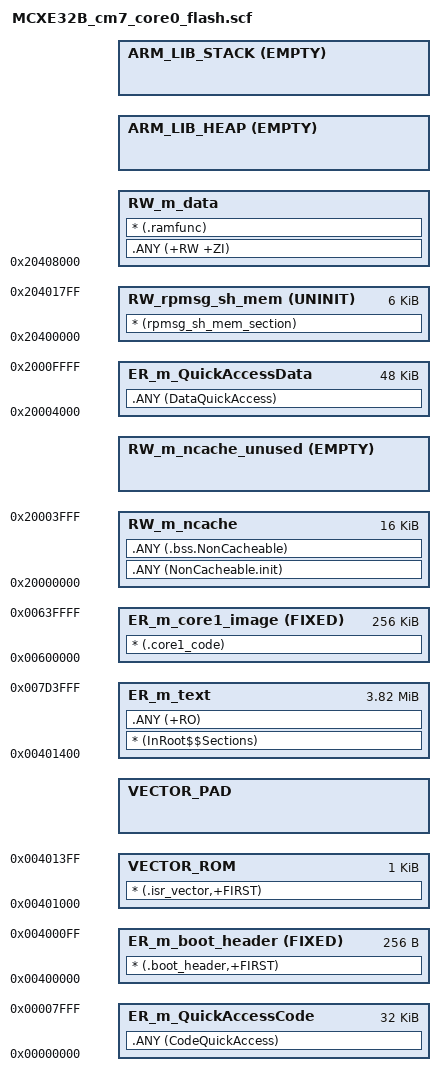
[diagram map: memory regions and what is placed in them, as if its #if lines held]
#!armclang --target=arm-arm-none-eabi -mcpu=cortex-m7 -E -x c

/*
** ###################################################################
**     Processor:           MCXE32BMPB_cm7_core0
**     Compiler:            Keil ARM C/C++ Compiler
**     Reference manual:    MCXE31 RM Rev2
**     Version:             rev. 1.1, 2025-11-07
**     Build:               b260609
**
**     Abstract:
**         Linker file for the Keil ARM C/C++ Compiler
**
**     Copyright 2016 Freescale Semiconductor, Inc.
**     Copyright 2016-2026 NXP
**     SPDX-License-Identifier: BSD-3-Clause
**
**     http:                 www.nxp.com
**     mail:                 support@nxp.com
**
** ###################################################################
*/

#define m_itcm_start                   0x00000000
#define m_itcm_end                     0x00007FFF

#define m_dtcm_start                   0x20000000
#define m_dtcm_end                     0x2000FFFF

#define m_stdby_ram_start              0x20400000
#define m_stdby_ram_end                0x20407FFF

#if (defined(__use_shmem__))
  #define rpmsg_sh_mem_size            0x1800
#else
  #define rpmsg_sh_mem_size            0
#endif
#define rpmsg_sh_mem_start             m_stdby_ram_start

#define m_interrupts_start             0x00401000
#define m_interrupts_size              0x00000400

#define m_boot_header_start            0x00400000
#define m_boot_header_size             0x00000100

#define m_text_start                   0x00401400
#define m_text_size                    0x003D2C00

/* Flash region holding the embedded secondary core (M7_1) image. The secondary
 * is linked to run in place from this address and is programmed together with
 * the primary. The secondary core is released by the application at runtime. */
#define m_core1_image_start            0x00600000
#define m_core1_image_size             0x00040000

/* Shared SRAM is split into two disjoint halves so the primary (M7_0) and the
 * secondary (M7_1) never use the same RAM. core0 owns the lower 144 KB; core1
 * owns the upper 144 KB (see MCXE32B_cm7_core1_flash.scf). The whole window is
 * 0x20408000..0x2044FFFF (288 KB). */
#define m_data_start                   0x20408000
#define m_data_size                    0x00024000

#define m_ncache_size                  0x00004000
#define m_ncache_start                 m_dtcm_start
#define m_ncache_end                   m_ncache_start + m_ncache_size - 1

#define m_qacode_start                 m_itcm_start
#define m_qacode_end                   m_itcm_end
#define m_qadata_start                 m_ncache_end + 1
#define m_qadata_end                   m_dtcm_end

#define m_itcm1_backdoor_start         0x11400000
#define m_itcm1_backdoor_size          0x00008000
#define m_itcm1_backdoor_end           m_itcm1_backdoor_start + m_itcm1_backdoor_size - 1

#define m_dtcm1_backdoor_start         0x21400000
#define m_dtcm1_backdoor_size          0x00010000
#define m_dtcm1_backdoor_end           m_dtcm1_backdoor_start + m_dtcm1_backdoor_size - 1

/* Sizes */
#if (defined(__stack_size__))
  #define Stack_Size                   __stack_size__
#else
  #define Stack_Size                   0x0400
#endif

#if (defined(__heap_size__))
  #define Heap_Size                    __heap_size__
#else
  #define Heap_Size                    0x0400
#endif

LR_m_header m_boot_header_start m_boot_header_size { ; load region size_region
  ER_m_boot_header m_boot_header_start FIXED m_boot_header_size { ; load address = execution address
    * (.boot_header,+FIRST)
  }
}

LR_m_text m_interrupts_start m_interrupts_size+m_text_size { ; load region size_region
  VECTOR_ROM m_interrupts_start m_interrupts_size { ; load address = execution address
    * (.isr_vector,+FIRST)
  }
  VECTOR_PAD +0 FILL 0x0 m_text_start-ImageLimit(VECTOR_ROM) {
  }
  ER_m_text m_text_start m_text_size { ; load address = execution address
    * (InRoot$$Sections)
    .ANY (+RO)
  }

  ER_m_QuickAccessCode   m_qacode_start      m_qacode_end-m_qacode_start+1
  {
    .ANY (CodeQuickAccess)
  }

  ER_m_QuickAccessData   m_qadata_start      m_qadata_end-m_qadata_start+1
  {
    .ANY (DataQuickAccess)
  }

  RW_m_ncache m_ncache_start  m_ncache_size
  {
    .ANY (NonCacheable.init)
    .ANY (.bss.NonCacheable)
  }

  ; Empty region added for MPU configuration
  RW_m_ncache_unused +0 EMPTY m_ncache_size-ImageLength(RW_m_ncache)
  {
  }

  RW_m_data m_data_start m_data_size-Stack_Size-Heap_Size { ; RW data
    .ANY (+RW +ZI)
    * (.ramfunc)
  }

  ARM_LIB_HEAP +0 EMPTY Heap_Size {    ; Heap region growing up
  }
  ARM_LIB_STACK m_data_start+m_data_size EMPTY -Stack_Size { ; Stack region growing down
  }
}

/* Embedded secondary core (M7_1) image, placed at a fixed flash address so it
 * is programmed together with the primary and runs in place from flash. */
LR_m_core1_image m_core1_image_start m_core1_image_size {
  ER_m_core1_image m_core1_image_start FIXED m_core1_image_size {
    * (.core1_code)
  }
}

/* rpmsg-lite shared memory (only consumes RAM when __use_shmem__ is defined). */
LR_rpmsg_sh_mem rpmsg_sh_mem_start rpmsg_sh_mem_size {
  RW_rpmsg_sh_mem rpmsg_sh_mem_start UNINIT rpmsg_sh_mem_size {
    * (rpmsg_sh_mem_section)
  }
}
